# R7FA0L107 register map
Vendor: Renesas Electronics Corporation; Series: RA0; File version: 1.10.01
CPU: CM23 r1p0, little endian, no MPU, no FPU, VTOR, 2 interrupt priority bits, 64 interrupts
Registers are 16-bit, read-write, reset 0x0 unless marked. A register's access mark holds for its fields unless they carry their own. Offsets are from the block's base; [hi:lo] are bit positions; {n}, {i} and the like mark numbered series.

## RTC_C — Realtime Clock
Base 0x400A2C00
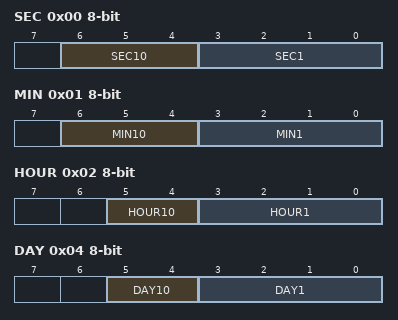
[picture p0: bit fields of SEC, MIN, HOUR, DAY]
0x00 SEC 8-bit (reset mask 0x80) — Second Count Register
  [6:4] SEC10 — 10-second count
  [3:0] SEC1 — 1-second count
0x01 MIN 8-bit (reset mask 0x80) — Minute Count Register
  [6:4] MIN10 — 10- minute count
  [3:0] MIN1 — 1-minute count
0x02 HOUR 8-bit (reset mask 0xC0) — Hour Count Register
  [5:4] HOUR10 — 10-hour count
  [3:0] HOUR1 — 1-hour count
0x03 WEEK 8-bit (reset mask 0xF8) — Day-of-Week Count Register
  [2:0] WEEK — Day-of-Week Counting
    0=Sunday; 1=Monday; 2=Tuesday; 3=Wednesday; 4=Thursday; 5=Friday; 6=Saturday; other=Others (Setting prohibited)
0x04 DAY 8-bit (reset mask 0xC0) — Day Count Register
  [5:4] DAY10 — 10-day count
  [3:0] DAY1 — 1-day count
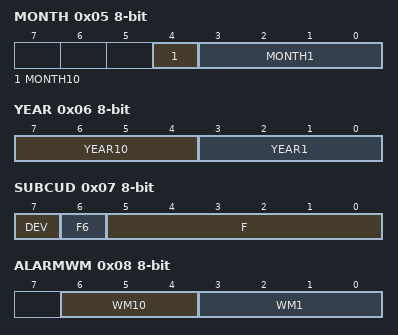
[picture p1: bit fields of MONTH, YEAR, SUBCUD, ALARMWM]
0x05 MONTH 8-bit (reset mask 0xE0) — Month Count Register
  [4] MONTH10 — 10-month count
  [3:0] MONTH1 — 1-month count
0x06 YEAR 8-bit reset not defined — Year Count Register
  [7:4] YEAR10 — 10-year count
  [3:0] YEAR1 — 1-year count
0x07 SUBCUD 8-bit — Time Error Correction Register
  [7] DEV — Setting of time error correction timing
    0=Corrects time error when the second digits are at 00, 20, or 40 (every 20 seconds); 1=Corrects time error only when the second digits are at 00 (every 60 seconds)
  [6] F6 — Setting of time error correction value
    0=Increases by {F[5:0] – 1} × 2; 1=Decreases by {/F[5:0] + 1} × 2
  [5:0] F — Adjustment Value
0x08 ALARMWM 8-bit (reset mask 0x80) — Alarm Minute Register
  [6:4] WM10 — 10-digit minute setting
  [3:0] WM1 — 1-digit minute setting
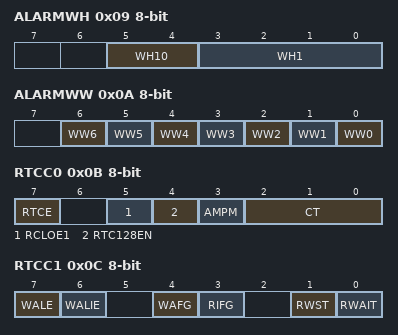
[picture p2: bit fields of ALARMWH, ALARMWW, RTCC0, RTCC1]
0x09 ALARMWH 8-bit (reset mask 0xC0) — Alarm Hour Register
  [5:4] WH10 — 10-digit hour setting
  [3:0] WH1 — 1-digit hour setting
0x0A ALARMWW 8-bit (reset mask 0x80) — Alarm Day-of-Week Register
  [all] fields
    0=Disable alarm settings for that day of the week; 1=Enable alarm settings for that day of the week
  [6] WW6 — Alarm enabled setting "Saturday"
  [5] WW5 — Alarm enabled setting "Friday"
  [4] WW4 — Alarm enabled setting "Thursday"
  [3] WW3 — Alarm enabled setting "Wednesday"
  [2] WW2 — Alarm enabled setting "Tuesday"
  [1] WW1 — Alarm enabled setting "Monday"
  [0] WW0 — Alarm enabled setting "Sunday"
0x0B RTCC0 8-bit — Realtime Clock Control Register 0
  [7] RTCE — Realtime clock operation control
    0=Stops counter operation; 1=Starts counter operation
  [5] RCLOE1 — RTCOUT pin output control
    0=Disables output of the RTCOUT pin (1 Hz); 1=Enables output of the RTCOUT pin (1 Hz)
  [4] RTC128EN — Selection of the operating clock for the realtime clock (RTCCLK)
    0=SOSC (32.768 kHz); 1=SOSC/256 (128 Hz)
  [3] AMPM — Selection of 12- or 24-hour system
    0=12-hour system (a.m. and p.m. are displayed.); 1=24-hour system
  [2:0] CT — Fixed-cycle interrupt (RTC_ALM_OR_PRD) selection
    0=Does not use fixed-cycle interrupt; 1=Once per 0.5 s (synchronously as the seconds count is updated); 2=Once per 1 s (at the same time as the seconds count is updated); 3=Once per 1 m (second 00 of every minute); 4=Once per 1 hour (minute 00 and second 00 of every hour); 5=Once per 1 day (hour 00, minute 00, and second 00 of every day); other=Others (Once per 1 month (Day 1, hour 00 a.m., minute 00, and second 00 of every month))
0x0C RTCC1 8-bit — Realtime Clock Control Register 1
  [7] WALE — Alarm operation control
    0=Match operation is invalid; 1=Match operation is valid
  [6] WALIE — Control of alarm interrupt (RTC_ALM_OR_PRD)
    0=Does not generate interrupt on matching of alarm; 1=Generates interrupt on matching of alarm
  [4] WAFG — Alarm detection status flag
    0=Alarm mismatch; 1=Detection of matching of alarm
  [3] RIFG — Fixed-cycle interrupt status flag
    0=Fixed-cycle interrupt is not generated; 1=Fixed-cycle interrupt is generated
  [1] RWST ro — Wait status flag of realtime clock
    0=Counting is in progress; 1=Counter values are readable and writable
  [0] RWAIT — Wait control of realtime clock
    0=Counting proceeds; 1=Stops the SEC to YEAR counters. Counter values are readable and writable.
